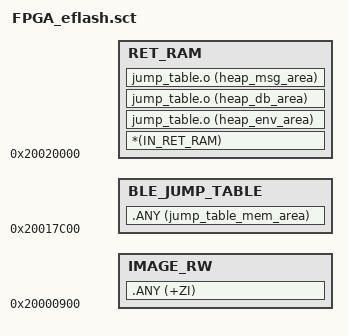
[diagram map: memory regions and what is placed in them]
        ; *************************************************************
; *** Scatter-Loading Description File generated by uVision ***
; *************************************************************

SOC 0x10010000 0x30000  ; 192KB
{
    STARTUP + 0 
    {
        *(VECTOR_TABLE, +First)
    }

    HEADER + 0 ;should be start from offset 0x08
    {
        *(IMAGE_HEADER, +First)        
    }

  
  
    IMAGE_RO + 0
    {
        *(InRoot$$Sections)
        .ANY (+RO)
    }

    IMAGE_RW 0x20000900      ; fixed address after BootROM BLE_ZI
    {
        *(RO_IN_SYS_RAM)
        ;*(RW_IN_SYS_RAM)
        ;clock.o (+RO, +RW, +ZI)
        .ANY (+RW)
    }

    IMAGE_ZI + 0
    {
        ;*(ZI_IN_SYS_RAM)
        .ANY (+ZI)
    }

    BLE_JUMP_TABLE 0x20017C00 
    {
        .ANY (jump_table_mem_area)
    }
      
    RET_RAM 0x20020000 ; Retention memory
    {        
        *(IN_RET_RAM)
        jump_table.o (heap_env_area)
        jump_table.o (heap_db_area)
        jump_table.o (heap_msg_area)
    }

}


